VERSION "BMW_E90_0.0.8"

NS_ :

BS_:

BU_: ABS ACSM CAS DIA DME DSC EKP FRM IHKA JBBF KOMBI RAD SZL TEL CCC Vector__XXX

CM_ "BMW E90 K-CAN 100 kbit/s";
CM_ "Maintained by Nicholas Berlette <https://github.com/nberlette>";

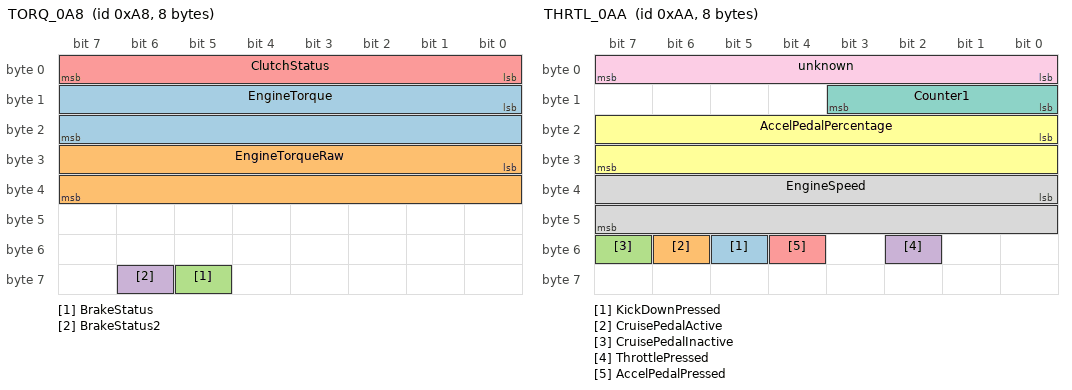
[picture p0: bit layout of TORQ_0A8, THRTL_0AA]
BO_ 168 TORQ_0A8: 8 DME
 SG_ EngineTorque : 8|16@1- (1,0) [-32768|65535] "" Vector__XXX
 SG_ EngineTorqueRaw : 24|16@1- (1,0) [-32768|65535] "" Vector__XXX
 SG_ BrakeStatus : 61|1@0+ (1,0) [0|1] "" Vector__XXX
 SG_ BrakeStatus2 : 62|1@0+ (1,0) [0|1] "" Vector__XXX
 SG_ ClutchStatus : 0|8@1+ (1,0) [0|0] "" Vector__XXX

CM_ BO_ 168 "0x0A8 TORQ (DME): Torque/Brake/Clutch Data";
CM_ SG_ 168 EngineTorque "Engine torque without inertia - combustion torque";
CM_ SG_ 168 EngineTorqueRaw "Engine torque without inertia and without shift intervention";
CM_ SG_ 168 BrakeStatus "Brake when driver presses the brake or hill hold";

BO_ 170 THRTL_0AA: 8 DME
 SG_ KickDownPressed : 53|1@0+ (1,0) [0|3] "" JBBF
 SG_ CruisePedalActive : 54|1@0+ (1,0) [0|1] "" JBBF
 SG_ CruisePedalInactive : 55|1@0+ (1,0) [0|1] "" JBBF
 SG_ ThrottlePressed : 50|1@0+ (1,0) [0|1] "" JBBF
 SG_ AccelPedalPressed : 52|1@0+ (1,0) [0|7] "" JBBF
 SG_ AccelPedalPercentage : 16|16@1+ (0.01,0) [0|100] "" JBBF
 SG_ Counter1 : 8|4@1+ (1,0) [0|15] "" JBBF
 SG_ EngineSpeed : 32|16@1- (1,0) [-32768|65535] "" JBBF
 SG_ unknown : 7|8@0- (1,0) [-128|65535] "" JBBF

CM_ BO_ 170 "0x0AA THRTL (DME): Throttle/Tachometer Data";
CM_ SG_ 170 ThrottlePressed "Active when accelerator pedal pressed or cruise control drives";
CM_ SG_ 170 AccelPedalPressed "Active only when driver actually presses the pedal";
CM_ SG_ 170 EngineSpeed "It's hard to say that is even a rate";

BO_ 184 DSC_0C0: 2 DSC
 SG_ Counter1 : 0|4@1+ (1,0) [0|15] "" Vector__XXX
 SG_ Counter2 : 8|4@1+ (1,0) [0|15] "" Vector__XXX

CM_ BO_ 184 "0x0C0 DSC: Counter";

BO_ 196 STEER_0C4: 7 SZL
 SG_ SteeringPosition : 0|16@1- (0.01,0) [-600|600] "deg" Vector__XXX
 SG_ SteeringSpeed : 24|16@1- (0.0428317,0) [-1403.5091456|255] "deg/s" Vector__XXX

CM_ BO_ 196 "0x0C4 STEER (SZL): Steering Wheel Data";
CM_ SG_ 196 SteeringPosition "Steering Wheel Position (deg)";
CM_ SG_ 196 SteeringSpeed "Steering Rotational Rate (deg/s)";

BO_ 200 STEER_0C8: 6 SZL
 SG_ SteeringPosition : 0|16@1- (0.0428317,0) [-600|600] "deg" Vector__XXX
 SG_ SteeringSpeed : 24|16@1- (0.0428317,0) [-65535|65535] "deg/s" Vector__XXX

CM_ BO_ 200 "0x0C8 STEER (SZL): Steering Wheel Data (slow)";
CM_ SG_ 200 SteeringPosition "Steering Wheel Position (deg)";
CM_ SG_ 200 SteeringSpeed "Steering Rotational Rate (deg/s)";

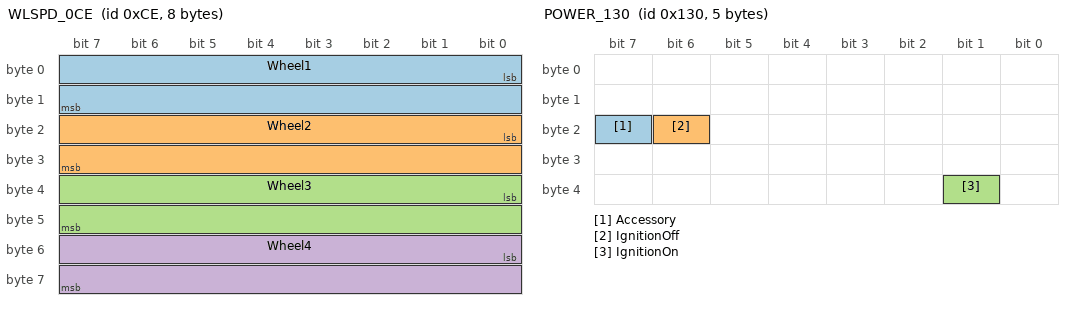
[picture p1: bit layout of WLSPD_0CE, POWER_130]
BO_ 206 WLSPD_0CE: 8 DSC
 SG_ Wheel1 : 0|16@1- (0.0643699,0) [-2109.2728832|255] "km/h" Vector__XXX
 SG_ Wheel2 : 16|16@1- (0.0643699,0) [-2109.2728832|255] "km/h" Vector__XXX
 SG_ Wheel3 : 32|16@1- (0.0643699,0) [-2109.2728832|255] "km/h" Vector__XXX
 SG_ Wheel4 : 48|16@1- (0.0643699,0) [-2109.2728832|255] "km/h" Vector__XXX

CM_ BO_ 206 "0x0CE WLSPD (DSC): Wheel Speeds (km/h)";

BO_ 209 ACCEL_0D1: 8 DME
 SG_ LateralAcceleration : 0|16@1- (1,0) [-32768|32768] "" JBBF
 SG_ LongitudalAcceleration : 32|16@1- (1,0) [-32768|65535] "" JBBF

CM_ BO_ 209 "0x0D1 ACCEL (DME): Accelerometer Data";

BO_ 215 ACSM_0D7: 2 JBBF

CM_ BO_ 215 "0x0D7 ACSM: Airbag Counter";

BO_ 226 DOOR_FL_0E2: 8 CAS

CM_ BO_ 226 "0x0E2 DOOR_FL (CAS): Front Driver Door (Front Left)";

BO_ 230 DOOR_RL_0E6: 8 CAS

CM_ BO_ 230 "0x0E6 DOOR_RL (CAS): Rear Driver Door (Rear Left)";

BO_ 234 DOOR_FR_0EA: 8 CAS

CM_ BO_ 234 "0x0EA DOOR_FR (CAS): Front Passenger Door (Front Right)";

BO_ 238 DOOR_RR_0EE: 8 CAS

CM_ BO_ 238 "0x0EE DOOR_RR (CAS): Rear Passenger Door (Rear Right)";

BO_ 242 BOOT_0F2: 8 CAS

CM_ BO_ 242 "0x0F2 BOOT (CAS): Trunk Status (Boot)";

BO_ 250 WIND_FL_0FA: 3 JBBF

CM_ BO_ 250 "0x0FA WIND_FL (JBBF): Drivers Window Controls (Front Left)";

BO_ 251 WIND_FR_0FB: 3 JBBF

CM_ BO_ 251 "0x0FB WIND_FR (JBBF): Passengers Window Controls (Front Right)";

BO_ 304 POWER_130: 5 JBBF
 SG_ Accessory : 23|1@0+ (1,0) [0|255] ""  Vector__XXX
 SG_ IgnitionOff : 22|1@0+ (1,0) [0|3] ""  Vector__XXX
 SG_ IgnitionOn : 33|1@0+ (1,0) [0|1] ""  Vector__XXX

CM_ BO_ 304 "0x130 POWER (JBBF): Terminal 15 (KL15)" ;
CM_ SG_ 304 Accessory "Active when key inserted, power on, engine off";
CM_ SG_ 304 IgnitionOn "Active when engine running";
CM_ SG_ 304 IgnitionOff "Active when engine off";

BO_ 309 FUEL_135: 8 EKP

CM_ BO_ 309 "0x135 FUEL (EKP): Crash Disconnect";

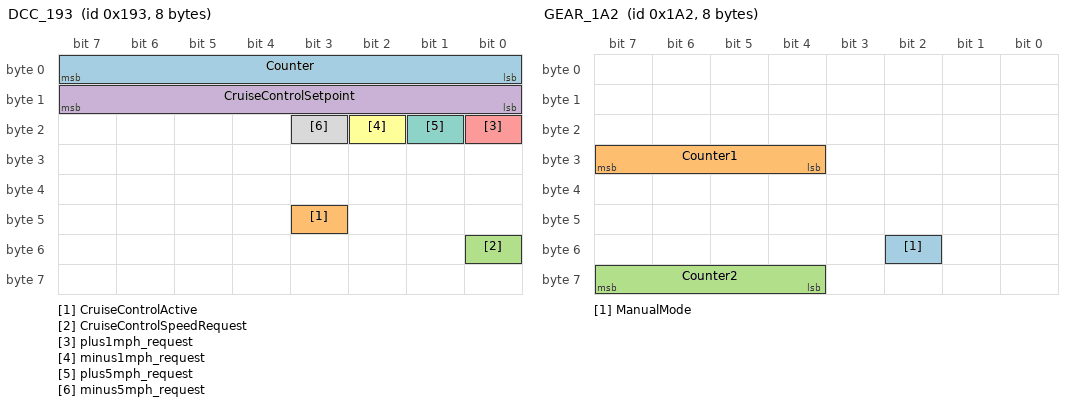
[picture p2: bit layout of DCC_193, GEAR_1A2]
BO_ 403 DCC_193: 8 KOMBI
 SG_ Counter : 7|8@0+ (1,0) [0|255] ""  Vector__XXX
 SG_ CruiseControlActive : 43|1@0+ (1,0) [0|1] ""  Vector__XXX
 SG_ CruiseControlSpeedRequest : 48|1@0+ (1,0) [0|1] ""  Vector__XXX
 SG_ CruiseControlSetpoint : 15|8@0+ (1,-2) [-2|255] "km/h"  Vector__XXX
 SG_ plus1mph_request : 16|1@0+ (1,0) [0|1] ""  Vector__XXX
 SG_ minus1mph_request : 18|1@0+ (1,0) [0|1] ""  Vector__XXX
 SG_ plus5mph_request : 17|1@0+ (1,0) [0|1] "" Vector__XXX
 SG_ minus5mph_request : 19|1@0+ (1,0) [0|1] "" Vector__XXX

CM_ BO_ 403 "0x193 DCC (KOMBI): Dynamic Cruise Control" ;
CM_ SG_ 403 CruiseControlSetpoint "Speed target - unit depends on locale";
CM_ SG_ 403 plus1mph_request "Appears when +1mph/kph stalk is depressed";
CM_ SG_ 403 minus1mph_request "Appears when -1mph/kph stalk is depressed";
CM_ SG_ 403 plus5mph_request "Appears when +5mph/kph stalk is depressed";
CM_ SG_ 403 minus5mph_request "Appears when -5mph/kph stalk is depressed";

BO_ 414 DSC_19E: 8 DSC

CM_ BO_ 414 "0x19E DSC: Status" ;

BO_ 418 GEAR_1A2: 8 DME
 SG_ ManualMode : 50|1@0+ (1,0) [0|255] ""  Vector__XXX
 SG_ Counter1 : 31|4@0+ (1,0) [0|14] ""  Vector__XXX
 SG_ Counter2 : 63|4@0+ (1,0) [0|15] ""  Vector__XXX

CM_ BO_ 418 "0x1A2 GEAR (DME): Gearbox Data" ;

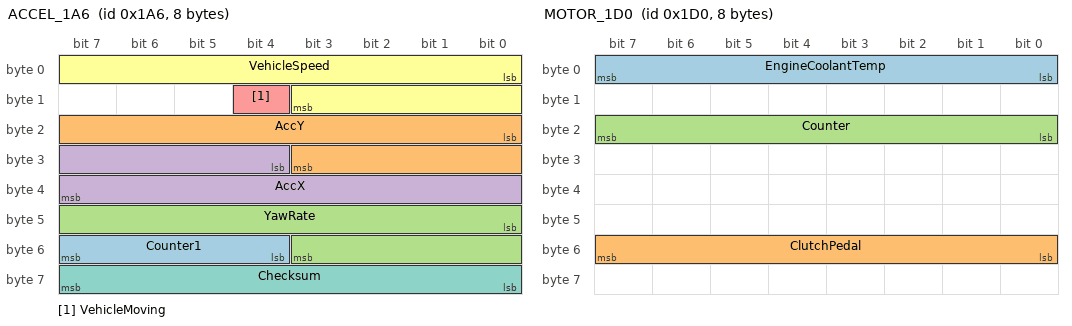
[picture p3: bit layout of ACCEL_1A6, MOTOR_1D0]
BO_ 422 ACCEL_1A6: 8 KOMBI
 SG_ Counter1 : 55|4@0+ (1,0) [0|14] ""  Vector__XXX
 SG_ AccY : 16|12@1- (1,0) [-2048|255] ""  Vector__XXX
 SG_ YawRate : 40|12@1- (1,0) [-2048|255] ""  Vector__XXX
 SG_ AccX : 28|12@1- (1,0) [-2048|15] ""  Vector__XXX
 SG_ VehicleMoving : 12|1@0+ (1,0) [0|1] ""  Vector__XXX
 SG_ VehicleSpeed : 0|12@1+ (0.103,0) [0|255] "km/h"  Vector__XXX
 SG_ Checksum : 63|8@0+ (1,0) [0|15] ""  Vector__XXX

CM_ BO_ 422 "0x1A6 ACCEL (KOMBI): Acceleration and Speed Data";
CM_ SG_ 422 AccY "Vertical Acceleration";
CM_ SG_ 422 AccX "Horizontal Acceleration";
CM_ SG_ 422 VehicleMoving "Is the vehicle moving?";
CM_ SG_ 422 YawRate "Lateral Acceleration";
VAL_ 422 VehicleMoving 1 "Moving" 0 "Stationary";

BO_ 436 BRAKE_1B4: 8 KOMBI
 SG_ HandbrakeStatus1 : 40|8@1+ (0.5,-24) [0|1] "" Vector__XXX

CM_ BO_ 436 "0x1B4 BRAKE (KOMBI): Speed and Handbrake Status" ;
VAL_ 436 HandbrakeStatus1 1 "Engaged" 0 "Disengaged" ;

BO_ 437 IHKA_1B5: 8 IHKA

CM_ BO_ 437 "0x1B5 IHKA: Heat Flow Climate" ;

BO_ 438 DME_1B6: 8 DME

CM_ BO_ 438 "0x1B6 DME: Heat Flow Engine" ;

BO_ 450 PDC_1C2: 8 PDC
 SG_ RearLeftSensor_1 0|8@1+ (1,0) [0|255] "cm" Vector__XXX
 SG_ RearLeftSensor_2 8|8@1+ (1,0) [0|255] "cm" Vector__XXX
 SG_ RearRightSensor_2 16|8@1+ (1,0) [0|255] "cm" Vector__XXX
 SG_ RearRightSensor_1 24|8@1+ (1,0) [0|255] "cm" Vector__XXX
 SG_ FrontLeftSensor_1 32|8@1+ (1,0) [0|255] "cm" Vector__XXX
 SG_ FrontLeftSensor_2 40|8@1+ (1,0) [0|255] "cm" Vector__XXX
 SG_ FrontRightSensor_2 48|8@1+ (1,0) [0|255] "cm" Vector__XXX
 SG_ FrontRightSensor_1 56|8@1+ (1,0) [0|255] "cm" Vector__XXX

CM_ BO_ 450 "0x1C2 PDC: Front and Reverse PDC Sensor Data" ;
CM_ BO_ 450 "RL_1/FL_1 is furthest to the left, RR_1/FR_1 is furthest to the right. 2 is in the middle." ;

BO_ 464 MOTOR_1D0: 8 DME
 SG_ EngineCoolantTemp : 0|8@1+ (1,-48) [0|207] "degC" Vector__XXX
 SG_ ClutchPedal : 48|8@1+ (1,-204) [0|1] "" Vector__XXX
 SG_ Counter : 23|8@0+ (1,0) [0|255] ""  Vector__XXX

CM_ BO_ 464 "0x1D0 MOTOR (DME): Engine Coolant Temperature";
VAL_ 464 ClutchPedal 0 "Released" 1 "Depressed" ;

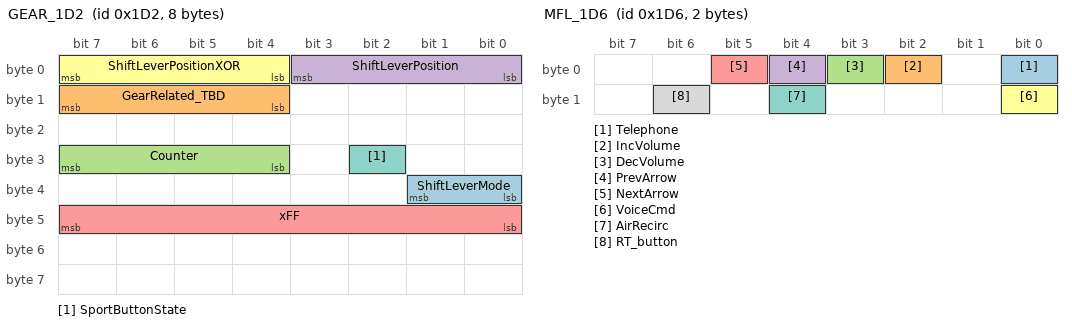
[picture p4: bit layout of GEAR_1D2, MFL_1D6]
BO_ 466 GEAR_1D2: 8 KOMBI
 SG_ ShiftLeverMode : 32|2@1+ (1,0) [0|3] ""  Vector__XXX
 SG_ GearRelated_TBD : 15|4@0+ (1,0) [0|15] ""  Vector__XXX
 SG_ Counter : 31|4@0+ (1,0) [0|14] ""  Vector__XXX
 SG_ ShiftLeverPosition : 0|4@1+ (1,0) [0|8] ""  Vector__XXX
 SG_ xFF : 47|8@0+ (1,0) [0|255] ""  Vector__XXX
 SG_ ShiftLeverPositionXOR : 4|4@1+ (1,0) [0|15] "" Vector__XXX
 SG_ SportButtonState : 26|1@1+ (1,0) [0|1] "" Vector__XXX

CM_ BO_ 466 "0x1D2 GEAR (KOMBI): Gearbox Data";
CM_ SG_ 466 ShiftLeverMode "On the dashboard is displayed:  D1...D6 in Normal. S1...S6 in Sport.  M1..M6 in Manual";
VAL_ 466 ShiftLeverMode 0 "Normal" 1 "Sport" 2 "Manual" ;
VAL_ 466 ShiftLeverPosition 0 "Off" 1 "P" 2 "R" 4 "N" 8 "D" ;

BO_ 470 MFL_1D6: 2 SZL
 SG_ Telephone : 0|1@0+ (1,0) [0|1] "" RAD
 SG_ IncVolume : 2|1@0+ (1,0) [0|1] "" RAD
 SG_ DecVolume : 3|1@0+ (1,0) [0|1] "" RAD
 SG_ PrevArrow : 4|1@0+ (1,0) [0|1] "" RAD
 SG_ NextArrow : 5|1@0+ (1,0) [0|1] "" RAD
 SG_ VoiceCmd : 8|1@0+ (1,0) [0|1] "" TEL
 SG_ AirRecirc : 12|1@0+ (1,0) [0|1] ""  IHKA
 SG_ RT_button : 14|1@0+ (1,0) [0|1] "" RAD

CM_ BO_ 470 "0x1D6 MFL (SZL): Steering Wheel Controls";
CM_  SG_ 470 Telephone "Telephone Button (answer/end call)";
CM_  SG_ 470 IncVolume "Increase Volume";
CM_  SG_ 470 DecVolume "Decrease Volume";
CM_  SG_ 470 NextArrow "Previous Track";
CM_  SG_ 470 PrevArrow "Next Track";
CM_  SG_ 470 VoiceCmd "Voice Command Button";
CM_  SG_ 470 AirRecirc "Air Recirculation Control (IHKA)";
CM_  SG_ 470 RT_button "Radio/Telephone Button";

BO_ 472 MFL_1D8: 2 SZL

CM_ BO_ 472 "0x1D8 MFL (SZL): Air Recirculation Button (?)";

BO_ 483 LIGHT_1E3: 2 FRM
 SG_ InteriorLightSwitchStatus : 0|1@1+ (1,0) [0|1] "" Vector__XXX

CM_ BO_ 483 "0x1E3 LIGHT (FRM): Interior Light Switch";
VAL_ 483 InteriorLightSwitchStatus 1 "Pressed" 0 "Released" ;

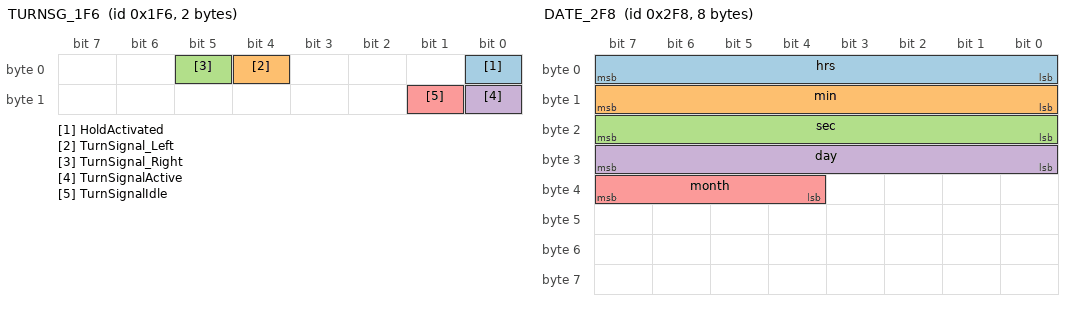
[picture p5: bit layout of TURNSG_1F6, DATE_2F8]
BO_ 502 TURNSG_1F6: 2 SZL
 SG_ HoldActivated : 0|1@1+ (1,0) [0|1] "" Vector__XXX
 SG_ TurnSignal_Left : 4|1@1+ (1,0) [0|1] "" Vector__XXX
 SG_ TurnSignal_Right : 5|1@0+ (1,0) [0|1] "" Vector__XXX
 SG_ TurnSignalActive : 8|1@0+ (1,0) [0|1] "" Vector__XXX
 SG_ TurnSignalIdle : 9|1@0+ (1,0) [0|1] "" Vector__XXX

CM_ BO_  502 "0x1F6 TRNSG (SZL): Turn Signal Switch";
CM_  SG_ 502 HoldActivated "Spikes down if blinker cleared with timeout or turn. Stays off if blinker cleared with stalk";
CM_  SG_ 502 TurnSignalActive "Turn signals active or transitioning";
CM_  SG_ 502 TurnSignalIdle "Turn signals inactive";
CM_  SG_ 502 TurnSignal_Left "Left turn signal is active";
CM_  SG_ 502 TurnSignal_Right "Right turn signal is active";

BO_ 514 LIGHT_202: 2 FRM

CM_ BO_  514 "0x202 LIGHT (FRM): Dimmer Status" ;

BO_ 538 LIGHT_21A: 3 FRM

CM_ BO_  538 "0x21A LIGHT (FRM): Lighting Status" ;

BO_ 550 RLS_226: 8 SZL

CM_ BO_  550 "0x226 RLS (SZL): Rain Sensor Wiper Speed" ;

BO_ 578 IHKA_242: 8 IHKA

CM_ BO_  578 "0x242 IHKA: Climate Front Status" ;

BO_ 678 RLS_2A6: 8 SZL
 SG_ AutoWipers : 0|1@1+ (1,0) [0|3] "" Vector__XXX

CM_ BO_  678 "0x2A6 RLS (SZL): Wiper Switch Status" ;
VAL_ 678 AutoWipers 1 "On" 0 "Off" ;

BO_ 690 TPMS_2B2: 8 DSC

CM_ BO_  690 "0x2B2 TPMS (DSC): Wheel Pressure" ;

BO_ 691 ACCEL_2B3: 8 DME

CM_ BO_  691 "0x2B3 ACCEL (DME) Acceleration Data" ;

BO_ 704 LIGHT_2C0: 3 FRM

CM_ BO_  704 "0x2C0 LIGHT (FRM): LCD Lighting" ;

BO_ 758 LIGHT_2F6: 8 FRM

CM_ BO_  758 "0x2F6 LIGHT (FRM): Light Control" ;

BO_ 760 DATE_2F8: 8 KOMBI
 SG_ hrs : 0|8@1+ (1,0) [0|60] "" Vector__XXX
 SG_ min : 8|8@1+ (1,0) [0|60] "" Vector__XXX
 SG_ sec : 16|8@1+ (1,0) [0|60] "" Vector__XXX
 SG_ day : 24|8@1+ (1,0) [0|31] "" Vector__XXX
 SG_ month : 36|4@1+ (1,0) [0|12] """ Vector__XXX
 SG_ year : 40|16@1+ (1,0) [1900|2200] "" Vector__XXX

CM_ BO_  760 "0x2F8 DATE (KOMBI): System Date and Time" ;
CM_  SG_ 760 month "Top 4 bits only, lower nibble is always 0xF. eg: Jan=0x1F,May=0x5F,Dec=0xCF" ;


BO_ 762 ACSM_2FA: 8 ACSM

CM_ BO_  762 "0x2FA ACSM: Seat Belt Contact" ;


BO_ 764 DOORS_2FC: 7 CAS

CM_ BO_  764 "0x2FC DOORS (CAS): Door Status" ;


BO_ 784 KOMBI_310: 8 KOMBI

CM_ BO_  784 "0x310 KOMBI: Ambient Temperature" ;


BO_ 797 TPMS_31D: 8 DSC

CM_ BO_  797 "0x31D TPMS (DSC): Tire Pressure" ;


BO_ 814 DATE_328: 8 KOMBI

CM_ BO_  814 "0x328 DATE (KOMBI): Reset Date and Time" ;


BO_ 816 ODOM_330: 8 KOMBI

CM_ BO_  816 "0x330 ODOM (KOMBI): Odometer" ;


BO_ 821 FUEL_335: 8 DME

CM_ BO_  821 "0x335 FUEL (DME): Electric Fuel Pump" ;


BO_ 823 FUEL_337: 8 EKP

CM_ BO_  823 "0x337 FUEL (EKP): Fuel Control" ;


BO_ 841 FUEL_349: 5 JBBF
 SG_ FuelSensorLeft : 0|16@1+ (0.00165108,0) [0|16.5] "gallons"
 SG_ FuelSensorRight: 16|16@1+ (0.00165108,0) [0|16.5] "gallons"

CM_ BO_  841 "0x349 FUEL (JBBF): Fuel Level Sensors" ;


BO_ 842  GPS_34A: 5 CCC

CM_ BO_  842 "0x34A GPS (CCC): GPS Position" ;


BO_ 847 BRAKE_34F: 2 KOMBI
 SG_ HandbrakeStatus2 : 1|1@1+ (1,0) [0|1] "" Vector__XXX

CM_ BO_  847 "0x34F BRAKE (KOMBI): Handbrake Status";
VAL_ 847 HandbrakeStatus2 1 "Enabled" 0 "Disabled" ;


BO_ 870 RANGE_366: 4 KOMBI
 SG_ ExternalTemperature : 0|8@1- (0.5,-80) [-40|87.5] "degC" Vector__XXX
 SG_ RemainingRange : 8|16@1+ (0.0625,0) [0|4096] "miles" Vector__XXX

CM_ BO_ 870 "0x366 RANGE (KOMBI): External Temp (degC) and Remaining Fuel Range (miles)" ;


BO_ 884 WLTOL_374: 8 DSC

CM_ BO_  884 "0x374 WLTOL (DSC): Wheel Tolerance Adjustment";


BO_ 896 VIN_380: 7 KOMBI

CM_ BO_  896 "0x380 VIN (KOMBI): Vehicle Identification Number (VIN)";


BO_ 897 OIL_381: 8 KOMBI

CM_ BO_  897 "0x381 OIL (KOMBI): Engine Oil Dipstick";


BO_ 940 POWER_3AC: 8 JBBF

CM_ BO_  940 "0x3AC POWER (JBBF): Terminal 30 (KL30)";


BO_ 944 RVRSE_3B0: 2 KOMBI
 SG_ ReverseGear : 6|1@1+ (1,0) [0|1] "" Vector__XXX

CM_ BO_  944 "0x3B0 RVRSE (KOMBI): Reverse Gear";
VAL_ 944 ReverseGear 1 "Engaged" 0 "Disengaged" ;


BO_ 945 GEAR_3B1: 8 DME
 SG_ Counter_1 : 0|5@1+ (1,0) [0|19] ""  JBBF
 SG_ Counter_2 : 8|4@1+ (1,0) [0|14] ""  JBBF

CM_ BO_  945 "0x3B1 GEAR (DME): Gearbox Data";


BO_ 947 POWER_3B3: 8 JBBF

CM_ BO_  947 "0x3B3 POWER (JBBF): Power Management";


BO_ 948 POWER_3B4: 8 JBBF
 SG_ BatteryVoltage : 7|24@0+ (0.001,0) [0|65535] ""  JBBF

CM_ BO_  948 "0x3B4 POWER (JBBF): Battery Voltage (?)";


BO_ 958 POWER_3BE: 8 JBBF

CM_ BO_  958 "0x3BE POWER (JBBF): Power Running Time";


BO_ 1007 OBD_3EF: 8 DIA

CM_ BO_  1007 "0x3EF OBD (DIA): Engine OBD Data";


BO_ 1554 DIAG_612: 8 DME

CM_ BO_  1554 "0x612 DIAG (DME): Diagnostic Response";


BO_ 1777 DIAG_6F1: 8 DIA

CM_ BO_  1777 "0x6F1 DIAG (DIA): Diagnostic Request";


BA_DEF_ BO_  "VFrameFormat" ENUM  "StandardCAN","ExtendedCAN","StandardFD","ExtendedFD","J1939PG";
BA_DEF_DEF_  "VFrameFormat" "StandardCAN" ;

BA_DEF_ BO_  "SystemMessageLongSymbol" STRING ;
BA_DEF_DEF_  "SystemMessageLongSymbol" "";

BA_DEF_ BO_  "GenMsgEVName" STRING ;
BA_DEF_DEF_  "GenMsgEVName" "" ;

BA_DEF_ BO_  "GenMsgDelayTime" INT 0 10000 ;
BA_DEF_DEF_  "GenMsgDelayTime" 0 ;

BA_DEF_ BO_  "GenMsgStartTime" INT 0 10000 ;
BA_DEF_DEF_  "GenMsgStartTime" 0 ;

BA_DEF_  SG_ "SystemSignalLongSymbol" STRING ;
BA_DEF_DEF_  "SystemSignalLongSymbol" "";
